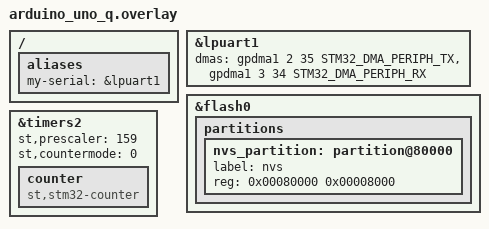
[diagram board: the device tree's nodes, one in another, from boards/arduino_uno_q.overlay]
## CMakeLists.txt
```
cmake_minimum_required(VERSION 3.20.0)

find_package(Zephyr REQUIRED HINTS $ENV{ZEPHYR_BASE})
project(imu_unoq_evk)

if(NOT DEFINED IMU_TARGET)
    set(IMU_TARGET "IM3J" CACHE STRING "IMU_TARGET is not defined, defaulting to IM3J")
endif()

if(IMU_TARGET STREQUAL "IM3J" OR IMU_TARGET STREQUAL "IM3J_STUB")
    set(IMU_INCLUDE_DIR ${CMAKE_CURRENT_SOURCE_DIR}/lib/IM3J)
    set(IMU_PLATFORM "IM3J")
elseif(IMU_TARGET STREQUAL "IM8S" OR IMU_TARGET STREQUAL "IM8S_STUB")
    set(IMU_INCLUDE_DIR ${CMAKE_CURRENT_SOURCE_DIR}/lib/IM8S)
    set(IMU_PLATFORM "IM8S")
else()
    message(FATAL_ERROR "Unsupported IMU_TARGET value: ${IMU_TARGET}")
endif()

if(IMU_TARGET STREQUAL "IM3J")
    target_compile_definitions(app PRIVATE -DSELECTED_PLATFORM_IM3J -DIMU_TARGET_IM3J)
    message(STATUS "Using IM3J code")
elseif(IMU_TARGET STREQUAL "IM3J_STUB")
    target_compile_definitions(app PRIVATE -DSELECTED_PLATFORM_IM3J -DIMU_TARGET_IM3J)
    message(STATUS "Using IM3J code (stub)")
elseif(IMU_TARGET STREQUAL "IM8S")
    target_compile_definitions(app PRIVATE -DSELECTED_PLATFORM_IM8S -DIMU_TARGET_IM8S)
    message(STATUS "Using IM8S code")
elseif(IMU_TARGET STREQUAL "IM8S_STUB")
    target_compile_definitions(app PRIVATE -DSELECTED_PLATFORM_IM8S -DIMU_TARGET_IM8S)
    message(STATUS "Using IM8S code (stub)")
endif()

if(IMU_TARGET STREQUAL "IM3J")
    add_library(DsImuSdk STATIC IMPORTED)
    set_target_properties(DsImuSdk PROPERTIES
        IMPORTED_LOCATION ${CMAKE_CURRENT_SOURCE_DIR}/lib/IM3J/DsImuSdk_Zephyr_CM33.a
    )
elseif(IMU_TARGET STREQUAL "IM8S")
    add_library(DsImuSdk STATIC IMPORTED)
    set_target_properties(DsImuSdk PROPERTIES
        IMPORTED_LOCATION ${CMAKE_CURRENT_SOURCE_DIR}/lib/IM8S/DsImuSdk_Zephyr_CM33.a
    )
elseif(IMU_TARGET STREQUAL "IM3J_STUB")
    add_library(DsImuSdk STATIC IMPORTED)
    set_target_properties(DsImuSdk PROPERTIES
        IMPORTED_LOCATION ${CMAKE_CURRENT_SOURCE_DIR}/lib/IM3J/DsImuSdk_placeholder.a
    )
elseif(IMU_TARGET STREQUAL "IM8S_STUB")
    add_library(DsImuSdk STATIC IMPORTED)
    set_target_properties(DsImuSdk PROPERTIES
        IMPORTED_LOCATION ${CMAKE_CURRENT_SOURCE_DIR}/lib/IM8S/DsImuSdk_placeholder.a
    )
endif()

target_include_directories(app PRIVATE
    ${CMAKE_CURRENT_SOURCE_DIR}/lib
    ${CMAKE_CURRENT_SOURCE_DIR}/src
    ${IMU_INCLUDE_DIR}
)

include_directories(${IMU_INCLUDE_DIR})

target_sources(app PRIVATE
    src/main.c
    src/zephyr_spi_hal.c
    src/zephyr_systick.c
    src/zephyr_async_uart.c
    src/uart_protocol.c
    src/Serial_Cmd.c
    src/nvs_config.c
)

target_compile_options(app PRIVATE
    -Wno-psabi
    -O2
)

target_link_libraries(app PRIVATE DsImuSdk stdc++)

set_property(TARGET app PROPERTY CXX_STANDARD 17)
```

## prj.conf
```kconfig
CONFIG_SPI=y
CONFIG_SPI_STM32=y
CONFIG_GPIO=y
CONFIG_PRINTK=y
CONFIG_LOG=y
CONFIG_LOG_DEFAULT_LEVEL=3

CONFIG_CPP=y
CONFIG_STD_CPP17=y
CONFIG_MINIMAL_LIBC=n
CONFIG_GLIBCXX_LIBCPP=y

CONFIG_HEAP_MEM_POOL_SIZE=65536
CONFIG_MAIN_STACK_SIZE=16384

CONFIG_CBPRINTF_FP_SUPPORT=y

CONFIG_FPU=y

CONFIG_SERIAL=y
CONFIG_UART_ASYNC_API=y
CONFIG_UART_INTERRUPT_DRIVEN=y

CONFIG_UART_CONSOLE=y

CONFIG_REBOOT=y

CONFIG_COUNTER=y
CONFIG_COUNTER_TIMER_STM32=y
CONFIG_CLOCK_CONTROL=y
CONFIG_SPEED_OPTIMIZATIONS=y

CONFIG_FLASH=y
CONFIG_FLASH_PAGE_LAYOUT=y
CONFIG_FLASH_MAP=y
CONFIG_MPU_ALLOW_FLASH_WRITE=y

CONFIG_SETTINGS=y
CONFIG_SETTINGS_NVS=y
CONFIG_NVS=y
CONFIG_MPU_ALLOW_FLASH_WRITE=y
```

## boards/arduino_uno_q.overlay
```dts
/ {
    aliases {
        my-serial = &lpuart1;
    };
};

&lpuart1 {
	dmas = <&gpdma1 2 35 STM32_DMA_PERIPH_TX>,
	       <&gpdma1 3 34 STM32_DMA_PERIPH_RX>;
	dma-names = "tx", "rx";
};

&flash0 {
    partitions {
        nvs_partition: partition@80000 {
            label = "nvs";
            reg = <0x00080000 0x00008000>;   /* 32 KB */
        };
    };
};

&timers2 {
    status = "okay";
    st,prescaler = <159>;  /* Set prescaler */
    st,countermode = <0>;         /* 0 = up-counting (default) */
    counter {
        compatible = "st,stm32-counter";
        status = "okay";
    };
};
```

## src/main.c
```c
#include <zephyr/kernel.h>
#include <zephyr/device.h>
#include <zephyr/drivers/spi.h>
#include <zephyr/drivers/counter.h>
#include <zephyr/drivers/gpio.h>
#include <zephyr/sys/printk.h>
#include <string.h>
#include <stdbool.h>

#include "DsImuSdk.h"
#include "zephyr_spi_hal.h"
#include "zephyr_async_uart.h"
#include "zephyr_systick.h"
#include "uart_protocol.h"
#include "nvs_config.h"

#define DsImuGetData_STACK_SIZE 3072
#define DsImuGetData_PRIORITY 6
#define UART1Send_STACK_SIZE 3072
#define UART1Send_PRIORITY 5
#define IMU_SAMPLE_PERIOD_US   (2000U)
#define IMU_FIFO_DATA_ARRAY_SIZE (10U)

K_THREAD_STACK_DEFINE(DsImuGetData_stack_area, DsImuGetData_STACK_SIZE);
K_THREAD_STACK_DEFINE(UART1Send_stack_area, UART1Send_STACK_SIZE);
K_SEM_DEFINE(uart_output, 0, 10);
K_SEM_DEFINE(imu_sample, 0, 10);

static const struct device* g_pCounter_dev = DEVICE_DT_GET(DT_CHILD(DT_NODELABEL(timers2), counter));

#define TIMER_NODE DT_ALIAS(my_counter)
static struct counter_alarm_cfg g_xImuSampleAlarm_cfg;
static struct counter_alarm_cfg g_xUartOutputAlarm_cfg;

static uint8_t SerialSendBuffer[SERIAL_SEND_BUFFER_SIZE];
static uint8_t UcSerialCmdBuffer[SERIAL_CMD_BUFF_SIZE];

bool gImuOutputEnabled = false;
bool gImuReinitFlag = false;
bool gImuSerialOutputEnabled = true;

static uint16_t SerialBufferIdx = 0;
static uint32_t sRxLen = 0;
//static uint32_t sUartProcDelayCompUs = 100;

static uint32_t gUartCurrentBaud = 921600U;   // Actual hardware baud rate
static uint32_t gUartDataBaud = 921600U;      // Configured baud rate for data output

static uint32_t gUartSendPeriodUs = 10000U;
/* Compensation control variables */
static uint64_t g_u64UartOutputExpectedUs = 0U;
static uint64_t g_u64ImuSampleExpectedUs = 0U;

typedef struct {
    DsImu_ImuCorrectedDataType xImuCorDataArray[IMU_FIFO_DATA_ARRAY_SIZE];
    uint8_t u8LatestIndex;
} Imu_Fifo_t;

static Imu_Fifo_t g_xImuFifo;

struct k_thread DsImuGetData_thread;
struct k_thread UART1Send_thread;

__attribute__((constructor(101))) static void __early_disable_alignment_check(void)
{
    *(volatile uint32_t*)0xE000ED14 &= ~(1UL << 3);
    __asm__ volatile("dsb sy" : : : "memory");
    __asm__ volatile("isb sy" : : : "memory");
}

void EnsureAlignmentCheckDisabled(void)
{
    static uint8_t checked = 0;
    if (!checked)
    {
        *(volatile uint32_t*)0xE000ED14 &= ~(1UL << 3);
        __asm__ volatile("dsb sy");
        __asm__ volatile("isb sy");
        checked = 1;
    }
}

static void Imu_fifo_push(const DsImu_ImuCorrectedDataType xImuCorData)
{
    uint8_t u8LatestIndex = g_xImuFifo.u8LatestIndex;
    u8LatestIndex = (u8LatestIndex + 1U) % IMU_FIFO_DATA_ARRAY_SIZE;
    (void)memcpy(&g_xImuFifo.xImuCorDataArray[u8LatestIndex], &xImuCorData, sizeof(DsImu_ImuCorrectedDataType));
    g_xImuFifo.u8LatestIndex = u8LatestIndex;
    if (g_xImuFifo.u8LatestIndex > IMU_FIFO_DATA_ARRAY_SIZE - 1U) {
        g_xImuFifo.u8LatestIndex = IMU_FIFO_DATA_ARRAY_SIZE - 1U;
    }
}

static void timer_callback(const struct device* dev, uint8_t chan_id, uint32_t ticks, void* user_data)
{
    (void)ticks;
    (void)user_data;
    uint64_t u64NowUs = k_cyc_to_us_floor64(k_cycle_get_64());
    int64_t i64Drift = 0;
    uint64_t u64AlarmUs = 0U;
    if (0U == chan_id) {
        /* Calculate expected trigger time */
        if (0U == g_u64ImuSampleExpectedUs) {
            /* First trigger, initialize */
            g_u64ImuSampleExpectedUs = u64NowUs;
        }
        else {
            g_u64ImuSampleExpectedUs += IMU_SAMPLE_PERIOD_US;
        }
        /* Calculate drift (positive = late, negative = early) */
        i64Drift = (int64_t)(u64NowUs - g_u64ImuSampleExpectedUs);

        /* ========== Core compensation algorithm ========== */
        /* If drift positive (late), advance next; if negative (early), delay next */
        u64AlarmUs = (uint64_t)((int64_t)IMU_SAMPLE_PERIOD_US - i64Drift);
        if ((u64AlarmUs < (IMU_SAMPLE_PERIOD_US - 100U)) || (u64AlarmUs > (IMU_SAMPLE_PERIOD_US + 100U))) {
            u64AlarmUs = IMU_SAMPLE_PERIOD_US;
        }
        g_xImuSampleAlarm_cfg.ticks = counter_us_to_ticks(dev, u64AlarmUs);
        //printk("now_us:%llu,expected_us:%llu,drift:%lld,alarm_us:%llu us\n", u64NowUs, g_u64ImuSampleExpectedUs, i64Drift, u64AlarmUs);
        if (true == gImuOutputEnabled) {
            counter_set_channel_alarm(dev, chan_id, &g_xImuSampleAlarm_cfg);
        }

        k_sem_give(&imu_sample);
    }
    else if (1U == chan_id) {
        /* Calculate expected trigger time */
        if (0U == g_u64UartOutputExpectedUs) {
            /* First trigger, initialize */
            g_u64UartOutputExpectedUs = u64NowUs;
        }
        else {
            g_u64UartOutputExpectedUs += gUartSendPeriodUs;
        }
        /* Calculate drift (positive = late, negative = early) */
        i64Drift = (int64_t)(u64NowUs - g_u64UartOutputExpectedUs);

        /* ========== Core compensation algorithm ========== */
        /* If drift positive (late), advance next; if negative (early), delay next */
        u64AlarmUs = (uint64_t)((int64_t)gUartSendPeriodUs - i64Drift);
        if ((u64AlarmUs < (gUartSendPeriodUs - 100U)) || (u64AlarmUs > (gUartSendPeriodUs + 100U))) {
            u64AlarmUs = gUartSendPeriodUs;
        }

        g_xUartOutputAlarm_cfg.ticks = counter_us_to_ticks(dev, u64AlarmUs);
        //printk("now_us:%llu,expected_us:%llu,drift:%lld,alarm_us:%llu us\n", u64NowUs, g_u64UartOutputExpectedUs, i64Drift, u64AlarmUs);

        counter_set_channel_alarm(dev, chan_id, &g_xUartOutputAlarm_cfg);
        k_sem_give(&uart_output);
    }
    else { /* do nothing. */
    }
}

static void UartCmdRxCallback(uint8_t* data, size_t len);

#if defined(IMU_TARGET_IM3J)
DsImu_CfgInfoType CfgInfo = {
    .module_type = MODULE_IM3J,
    .acc_fs = IM3J_FS_XL_6_G, /**< Accelerometer full-scale code. */
    .gyr_fs = IM3J_FS_GY_1000_DPS, /**< Gyroscope full-scale code. */
    .acc_odr = IM3J_XL_ODR_200_HZ, /**< Accelerometer output data rate. */
    .acc_lpf = IM3J_XL_LPF_OSR4, /**< Accelerometer low-pass filter. */
    .gyr_lpf = IM3J_GY_ODR_200_LPF_23_HZ, /**< Gyroscope ODR and LPF. */
    .tim_freq = FREQ_500HZ, /**< Timer frequency [Hz]. */
    .u32SpiTimeoutUs[0] = 10000U, /**< [us] */
    .u32SpiTimeoutUs[1] = 10000U, /**< [us] */
    .u64UsTickValueMax = 0xFFFFFFFFFFFFFFFFU,
    .mcu_freq = 160U,
    .transfer = spiTransfer,
    .cancel = spiCancel,
    .systick = GetTickUs,
    .getStatus = spiGetTransferResult,
    .fMntAng = {0.0F, 0.0F, 0.0F},
    .fExtAng = {0.0F, 0.0F, 0.0F},
    .fPos = {0.0F, 0.0F, 0.0F}
};

#elif defined(IMU_TARGET_IM8S)
DsImu_CfgInfoType CfgInfo = {
    .module_type = MODULE_IM8S,
    .acc_fs = IM8S_FS_XL_8_G, /**< Accelerometer full-scale code. */
    .gyr_fs = IM8S_FS_GY_250_DPS, /**< Gyroscope full-scale code. */
    .acc_odr = BYPASS, /**< Accelerometer ODR. */
    .acc_lpf = IM8S_XL_LPF_16HZ, /**< Accelerometer low-pass filter. */
    .gyr_lpf = IM8S_GY_LPF_50HZ, /**< Gyroscope low-pass filter. */
    .tim_freq = FREQ_500HZ, /**< Timer frequency [Hz]. */
    .u32SpiTimeoutUs[0] = 10000U, /**< [us] */
    .u32SpiTimeoutUs[1] = 10000U, /**< [us] */
    .u64UsTickValueMax = 0xFFFFFFFFFFFFFFFFU,
    .mcu_freq = 160U,
    .transfer = spiTransfer,
    .cancel = spiCancel,
    .systick = GetTickUs,
    .getStatus = spiGetTransferResult,
    .fMntAng = {0.0F, 0.0F, 0.0F},
    .fExtAng = {0.0F, 0.0F, 0.0F},
    .fPos = {0.0F, 0.0F, 0.0F}
};
#endif

static DsImu_ImuCorrectedDataType xImuCorData;
static DsImu_ImuRawDataType xImuRawData;
static DsImu_InfoType xInfo;
static bool sDsImuSdkInitFlag = false;

static void Counter_Config(const struct device* counter_dev)
{
    int ret = 0;
    uint32_t u32ImuSamplePeriodUs = IMU_SAMPLE_PERIOD_US;  /* 2ms */
    uint32_t u32ImuSampleAlarmTicks = 0U;
    uint32_t u32UartOutputPeriodUs = gUartSendPeriodUs;
    uint32_t u32UartOutputAlarmTicks = 0U;

    if (!device_is_ready(counter_dev)) {
        printk("Counter device not ready!\n");
        return;
    }
    printk("Counter device found: %s\n", counter_dev->name);

    /* Get timer actual frequency (for validation) */
    uint32_t freq = counter_get_frequency(counter_dev);
    printk("Timer frequency: %u Hz\n", freq);

    /* Convert Imu microseconds to ticks (based on actual frequency) */
    u32ImuSampleAlarmTicks = counter_us_to_ticks(counter_dev, u32ImuSamplePeriodUs);
    printk("ImuSamplePeriodUs: %u us -> %u ticks\n", u32ImuSamplePeriodUs, u32ImuSampleAlarmTicks);
    g_xImuSampleAlarm_cfg.callback = timer_callback;
    g_xImuSampleAlarm_cfg.ticks = u32ImuSampleAlarmTicks;
    g_xImuSampleAlarm_cfg.user_data = NULL;
    g_xImuSampleAlarm_cfg.flags = 0U;

    //   ret = counter_set_channel_alarm(counter_dev, 0, &g_xImuSampleAlarm_cfg);
    //   if (ret != 0) {
    //       printk("Failed to set alarm (err: %d)\n", ret);
    //       return;
    //   }

    u32UartOutputAlarmTicks = counter_us_to_ticks(counter_dev, u32UartOutputPeriodUs);
    printk("UartOutputPeriodUs: %u us -> %u ticks\n", u32UartOutputPeriodUs, u32UartOutputAlarmTicks);
    g_xUartOutputAlarm_cfg.callback = timer_callback;
    g_xUartOutputAlarm_cfg.ticks = u32UartOutputAlarmTicks;
    g_xUartOutputAlarm_cfg.user_data = NULL;
    g_xUartOutputAlarm_cfg.flags = 0U;

    ret = counter_set_channel_alarm(counter_dev, 1, &g_xUartOutputAlarm_cfg);
    if (ret != 0) {
        printk("Failed to set alarm (err: %d)\n", ret);
        return;
    }

    ret = counter_start(counter_dev);
    if (ret != 0) {
        printk("Failed to start counter (err: %d)\n", ret);
        return;
    }

    printk("Timer started!\n");
}

// static uint64_t g_u64LastTick = 0U;
void DsImuGetData_entry_point(void* p1, void* p2, void* p3)
{
#if defined(IMU_TARGET_IM3J)
    for (;;)
    {
        if ((gImuOutputEnabled == false) || (gImuReinitFlag))
        {
            if (gImuReinitFlag)
            {
                gImuReinitFlag = 0;
                //printk("Reinit IMU...\n");
            }
            else
            {
                //printk("IMU First Start...\n");
            }

            if (DsImu_Init(&CfgInfo) == 0)
            {
                //printk("DsImu SDK Init Success!\n");
                gImuOutputEnabled = true;
                g_u64ImuSampleExpectedUs = 0U;
                counter_set_channel_alarm(g_pCounter_dev, 0, &g_xImuSampleAlarm_cfg);
            }
            else
            {
                //printk("IMU Init FAIL\n");
            }
        }
        k_sem_take(&imu_sample, K_FOREVER);
        //uint64_t u64Us = k_cyc_to_us_floor64(k_cycle_get_64());
        //uint64_t u64diff = u64Us - g_u64LastTick;
        //g_u64LastTick = u64Us;
        //uint64_t u64Us2 = 0U;
        //uint64_t u64Us3 = 0U;
        if (gImuOutputEnabled)
        {
            //u64Us2 = k_cyc_to_us_floor64(k_cycle_get_64());
            DsImuGetDataStatus_t eGetDataStatus =
                DsImu_GetData(&xImuCorData, &xImuRawData);
            //u64Us3 = k_cyc_to_us_floor64(k_cycle_get_64());
            Imu_fifo_push(xImuCorData);
            if (eGetDataStatus == GET_SUCCESS)
            {

            }
            else if (eGetDataStatus == GET_DATA_NOT_READY)
            {

            }
            else if (eGetDataStatus == GET_ERR_RESET)
            {
                gImuOutputEnabled = false;
                gImuReinitFlag = true;
            }
            else
            {
                //printk("DsImu Get Data Error! Code: %d\n", eGetDataStatus);
            }
        }
        //printk("Tick:%llu, diff:%llu us, GetDataRun:%llu us\n", u64Us, u64diff, u64Us3 - u64Us2);
//k_msleep(10);
    }

#elif defined(IMU_TARGET_IM8S)

    for (;;)
    {
        if ((gImuOutputEnabled == false) || (gImuReinitFlag))
        {
            if (gImuReinitFlag)
            {
                gImuReinitFlag = 0;
                //printk("Reinit IMU...\n");
            }
            else
            {
                //printk("IMU First Start...\n");
            }

            DsImuInitStatus_t ret = DsImu_Init(&CfgInfo);

            if (ret == INIT_SUCCESS)
            {
                gImuOutputEnabled = true;
                //printk("DsImu SDK Init Success!\n");
                uint8_t eStatus_GetInfo = DsImu_GetInfo(&xInfo);
                if (eStatus_GetInfo == 0U)
                {
                    //printk("DsImu SDK GetInfo Success!\n");
                }
                else {
                    //printk("DsImu SDK GetInfo Failed! Error Code: %d\n", eStatus_GetInfo);
                }
                sDsImuSdkInitFlag = true;
                g_u64ImuSampleExpectedUs = 0U;
                counter_set_channel_alarm(g_pCounter_dev, 0, &g_xImuSampleAlarm_cfg);
            }
            else
            {
                //printk("IMU Init FAIL! Error Code:%d\n", ret);
            }
        }
        k_sem_take(&imu_sample, K_FOREVER);
        //uint64_t u64Us = k_cyc_to_us_floor64(k_cycle_get_64());
        //uint64_t u64diff = u64Us - g_u64LastTick;
        //g_u64LastTick = u64Us;
        //uint64_t u64Us2 = 0U;
        //uint64_t u64Us3 = 0U;
        if (gImuOutputEnabled)
        {
            //u64Us2 = k_cyc_to_us_floor64(k_cycle_get_64());
            DsImuGetDataStatus_t eGetDataStatus =
                DsImu_GetData(&xImuCorData, &xImuRawData);
            //u64Us3 = k_cyc_to_us_floor64(k_cycle_get_64());
            Imu_fifo_push(xImuCorData);
            if (eGetDataStatus == GET_SUCCESS)
            {

            }
            else if (eGetDataStatus == GET_ERR_RESET)
            {
                gImuOutputEnabled = false;
                gImuReinitFlag = true;
            }
            else
            {
                //printk("DsImu Get Data Error! Code: %d\n", eGetDataStatus);
            }
        }
        //printk("Tick:%llu, diff:%llu us, GetDataRun:%llu us\n", u64Us, u64diff, u64Us3 - u64Us2);
//k_msleep(10);
    }
#endif
}

void UART1Send_entry_point(void* p1, void* p2, void* p3)
{
    while (1)
    {
        /* Wait for semaphore (block until data available) */
        k_sem_take(&uart_output, K_FOREVER);
        //uint64_t u64Us = k_cyc_to_us_floor64(k_cycle_get_64());
        //uint64_t u64diff = u64Us - g_u64LastTick;
        //g_u64LastTick = u64Us;
        if (gImuSerialOutputEnabled)
        {
            SerialBufferIdx = Composer_PrintImu(
                SerialSendBuffer,
                &g_xImuFifo.xImuCorDataArray[g_xImuFifo.u8LatestIndex]);

            SerialSendMsg(
                SerialSendBuffer,
                SerialBufferIdx);
            //printk("Tick:%llu, diff: %llu us\n", u64Us, u64diff);
            //printk("Running!\r\n");
        }
        //k_usleep(gUartSendPeriodUs - sUartProcDelayCompUs);
    }
}

void setUartSendPeriodUs(const uint32_t u32UartSendPeriodUs)
{
    gUartSendPeriodUs = u32UartSendPeriodUs;
    g_u64UartOutputExpectedUs = 0U;
    //printk("UartSetPeriod:%u\n", gUartSendPeriodUs);
}

uint32_t GetUartSendPeriodUs(void) { return gUartSendPeriodUs; }

// Current hardware baud rate
void setUartCurrentBaud(const uint32_t baud) { gUartCurrentBaud = baud; }
uint32_t GetUartCurrentBaud(void) { return gUartCurrentBaud; }

// Configured baud rate for data output
void setUartBaud(const uint32_t baud) { gUartDataBaud = baud; }
uint32_t GetUartBaud(void) { return gUartDataBaud; }


int main(void)
{
    EnsureAlignmentCheckDisabled();
    UartRxCbRegister(UartCmdRxCallback);

    const struct device* spi_dev = DEVICE_DT_GET(DT_NODELABEL(spi2));
    if (!device_is_ready(spi_dev))
    {
        //printk("SPI2 not ready\n");
        return 0;
    }

    //counter_dev = DEVICE_DT_GET_ANY(st_stm32_counter);
    if (g_pCounter_dev) {
        printk("The selected counter device is: %s\n", g_pCounter_dev->name);
    }

    TickInit();
    Zephyr_SPI_GPIO_Init();

    /* ====== Load NVS configuration ====== */
    int nvs_rc = NvsConfigInit();
    if (nvs_rc == 0) {
        StoredConfig_t stored;
        if (NvsConfigLoad(&stored) == 0) {
            /* Override default values */
            gUartDataBaud = stored.baud_rate;
            gUartSendPeriodUs = stored.send_period_us;
            CfgInfo.acc_fs = stored.acc_fs;
            CfgInfo.gyr_fs = stored.gyr_fs;
            CfgInfo.acc_odr = stored.acc_odr;
            CfgInfo.acc_lpf = stored.acc_lpf;
            CfgInfo.gyr_lpf = stored.gyr_lpf;
            printk("NVS: config loaded, baud=%u, period=%u\n",
                gUartDataBaud, gUartSendPeriodUs);
        }
    }

    Counter_Config(g_pCounter_dev);

    (void)memset(&g_xImuFifo.xImuCorDataArray[0], 0, sizeof(DsImu_ImuCorrectedDataType));
    g_xImuFifo.u8LatestIndex = 9U;

    k_thread_create(&DsImuGetData_thread,
        DsImuGetData_stack_area,
        K_THREAD_STACK_SIZEOF(DsImuGetData_stack_area),
        DsImuGetData_entry_point,
        NULL, NULL, NULL,
        DsImuGetData_PRIORITY,
        0,
        K_NO_WAIT);

    k_thread_create(&UART1Send_thread,
        UART1Send_stack_area,
        K_THREAD_STACK_SIZEOF(UART1Send_stack_area),
        UART1Send_entry_point,
        NULL, NULL, NULL,
        UART1Send_PRIORITY,
        0,
        K_NO_WAIT);
    return 0;
}

static void UartCmdRxCallback(uint8_t* data, size_t len)
{
    for (int i = 0; i < len; i++)
    {
        uint8_t byte = data[i];

        if (sRxLen >= SERIAL_CMD_BUFF_SIZE)
        {
            sRxLen = 0;
        }

        UcSerialCmdBuffer[sRxLen++] = byte;

        if (byte == '\n')
        {
            ProcessSerialBuffer(UcSerialCmdBuffer, &sRxLen);
        }
    }

    k_free(data);
}
```

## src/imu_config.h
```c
#ifndef IMU_CONFIG_H
#define IMU_CONFIG_H

#include "DsImuSdk.h"

extern DsImu_CfgInfoType CfgInfo;

#endif
```

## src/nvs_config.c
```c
#include "nvs_config.h"
#include <zephyr/kernel.h>
#include <zephyr/device.h>
#include <zephyr/drivers/flash.h>
#include <zephyr/storage/flash_map.h>
#include <zephyr/kvss/nvs.h>
#include <string.h>

/* ====== Obtain partition information directly using devicetree ====== */
#define NVS_PARTITION_NODE  DT_NODELABEL(nvs_partition)

#define NVS_FLASH_DEVICE    DEVICE_DT_GET(DT_MTD_FROM_FIXED_PARTITION(NVS_PARTITION_NODE))
#define NVS_OFFSET          DT_REG_ADDR(NVS_PARTITION_NODE)
#define NVS_SIZE            DT_REG_SIZE(NVS_PARTITION_NODE)

#define NVS_SECTOR_SIZE     8192U
#define NVS_SECTOR_COUNT    (NVS_SIZE / NVS_SECTOR_SIZE)

static struct nvs_fs g_nvs_fs;
static bool g_nvs_ready = false;

static uint8_t Config_CRC8(const uint8_t* buf, uint16_t len)
{
    uint8_t crc = 0;
    for (uint16_t i = 0; i < len; i++) {
        crc ^= buf[i];
        for (uint8_t j = 0; j < 8; j++) {
            if (crc & 0x80)
                crc = (crc << 1) ^ 0x07;
            else
                crc <<= 1;
        }
    }
    return crc;
}

/* ====== Initialize NVS ====== */
int NvsConfigInit(void)
{
    int rc;

    if (!device_is_ready(NVS_FLASH_DEVICE)) {
        printk("NVS: Flash device not ready\n");
        return -ENODEV;
    }

    g_nvs_fs.flash_device = NVS_FLASH_DEVICE;
    g_nvs_fs.offset = NVS_OFFSET;
    g_nvs_fs.sector_size = NVS_SECTOR_SIZE;
    g_nvs_fs.sector_count = NVS_SECTOR_COUNT;

    rc = nvs_mount(&g_nvs_fs);
    if (rc) {
        printk("NVS: mount failed (%d), formatting...\n", rc);
        /* Perform a clean installation or data restoration if it is the first time use or if the data is damaged. */
        rc = nvs_clear(&g_nvs_fs);
        if (rc) {
            printk("NVS: clear failed: %d\n", rc);
            return rc;
        }
        rc = nvs_mount(&g_nvs_fs);
        if (rc) {
            printk("NVS: re-mount after clear failed: %d\n", rc);
            return rc;
        }
    }

    g_nvs_ready = true;
    printk("NVS: ready, offset=0x%lx, size=%u\n",
        (unsigned long)NVS_OFFSET, (unsigned int)NVS_SIZE);
    return 0;
}

/* ====== Load configuration ====== */
int NvsConfigLoad(StoredConfig_t* cfg)
{
    ssize_t read_len;

    if (!cfg)      return -EINVAL;
    if (!g_nvs_ready) return -EAGAIN;

    read_len = nvs_read(&g_nvs_fs, NVS_ID_CONFIG, cfg, sizeof(StoredConfig_t));
    if (read_len < 0) {
        printk("NVS: config not found (rc=%d), using defaults\n", (int)read_len);
        return 1;  /* No stored data uses default values */
    }
    if (read_len != sizeof(StoredConfig_t)) {
        printk("NVS: config size mismatch (%d != %d)\n",
            (int)read_len, (int)sizeof(StoredConfig_t));
        return -EIO;
    }

    /* Verify magic */
    if (cfg->magic != NVS_CONFIG_MAGIC) {
        printk("NVS: bad magic 0x%08X (expected 0x%08X)\n",
            (unsigned)cfg->magic, (unsigned)NVS_CONFIG_MAGIC);
        return 1;
    }

    uint8_t calc_crc = Config_CRC8((const uint8_t*)cfg,
        sizeof(StoredConfig_t) - 3);
    if (calc_crc != cfg->crc) {
        printk("NVS: CRC mismatch (calc=0x%02X, stored=0x%02X)\n",
            calc_crc, cfg->crc);
        return -EIO;
    }

    printk("NVS: config loaded OK\n");
    return 0;
}

/* ====== Save configuration ====== */
int NvsConfigSave(const StoredConfig_t* cfg)
{
    int rc;
    StoredConfig_t wr_cfg;

    if (!cfg)         return -EINVAL;
    if (!g_nvs_ready) return -EAGAIN;

    memcpy(&wr_cfg, cfg, sizeof(StoredConfig_t));
    wr_cfg.magic = NVS_CONFIG_MAGIC;
    wr_cfg.crc = Config_CRC8((const uint8_t*)&wr_cfg,
        sizeof(StoredConfig_t) - 3);
    wr_cfg.reserved[0] = 0xFF;
    wr_cfg.reserved[1] = 0xFF;

    rc = nvs_write(&g_nvs_fs, NVS_ID_CONFIG, &wr_cfg, sizeof(StoredConfig_t));
    if (rc < 0) {
        printk("NVS: write failed: %d\n", rc);
        return rc;
    }

    printk("NVS: config saved OK\n");
    return 0;
}

/* ====== Erasure of configuration ====== */
int NvsConfigErase(void)
{
    if (!g_nvs_ready) return -EAGAIN;

    int rc = nvs_delete(&g_nvs_fs, NVS_ID_CONFIG);
    if (rc < 0 && rc != -ENOENT) {
        printk("NVS: erase failed: %d\n", rc);
        return rc;
    }
    printk("NVS: config erased\n");
    return 0;
}
```

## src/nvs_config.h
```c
#ifndef NVS_CONFIG_H
#define NVS_CONFIG_H

#include <stdint.h>
#include <stdbool.h>

#define NVS_CONFIG_MAGIC    0xDA15C401   /* "UIMU" */

#if defined(IMU_TARGET_IM3J)
#define NVS_ID_CONFIG       0x0001       /* Configuration of IM3J*/
#elif defined(IMU_TARGET_IM8S)
#define NVS_ID_CONFIG       0x0002       /* Configuration of IM8S*/
#else
#define NVS_ID_CONFIG       0x0001       /* default */
#endif

typedef struct __attribute__((packed)) {
    uint32_t magic;           /* Magic number, used to determine whether it has been written before */
    uint32_t baud_rate;       /* gUartDataBaud */
    uint32_t send_period_us;  /* gUartSendPeriodUs */
    uint8_t  acc_fs;          /* CfgInfo.acc_fs */
    uint8_t  gyr_fs;          /* CfgInfo.gyr_fs */
    uint8_t  acc_odr;         /* CfgInfo.acc_odr */
    uint8_t  acc_lpf;         /* CfgInfo.acc_lpf */
    uint8_t  gyr_lpf;         /* CfgInfo.gyr_lpf */
    uint8_t  crc;             /* CRC */
    uint8_t  reserved[2];     /* Align and pad */
} StoredConfig_t;

/**
 * @brief Initialize NVS (mount partition)
 * @return 0 on success, negative on failure
 */
int NvsConfigInit(void);

/**
 * @brief Load configuration from NVS
 * @param cfg Output parameter, loaded into this structure
 * @return 0=success, 1=no stored data (first boot), negative=error
 */
int NvsConfigLoad(StoredConfig_t* cfg);

/**
 * @brief Save configuration to NVS
 * @param cfg Configuration to be saved
 * @return 0 on success, negative on failure
 */
int NvsConfigSave(const StoredConfig_t* cfg);

/**
 * @brief Erase configuration in NVS (for factory reset)
 * @return 0 on success, negative on failure
 */
int NvsConfigErase(void);

#endif /* NVS_CONFIG_H */
```

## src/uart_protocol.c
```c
#include "uart_protocol.h"
#include <stdio.h>
#include <string.h>
#include "zephyr_systick.h"
#include "DsImuSdk.h"

uint8_t u8count;
uint8_t u8bincount;
uint8_t crc_ack;
int16_t i16temp;

uint8_t CRC_8(uint8_t* buf, uint16_t len)
{
    uint8_t crc = 0;

    for (uint16_t i = 0; i < len; i++)
    {
        crc ^= buf[i];
        for (uint8_t j = 0; j < 8; j++)
        {
            if (crc & 0x80)
                crc = (crc << 1) ^ 0x07;
            else
                crc <<= 1;
        }
    }
    return crc;
}

int Composer_PrintImu(unsigned char* pStr, DsImu_ImuCorrectedDataType* pxSendData)
{
    uint8_t u8binhead[3] = { 0XA5, 0X5A, 0X00 };
    uint8_t u8end[2] = { 0X0D, 0X0A };
    uint64_t u64UnixTime;
    uint8_t u8cmdlen[2] = { 0X10, 0X40 };
    uint8_t idx = 0;
    int16_t i16temp;
    uint8_t crc_ack;

    if (u8bincount < 255) {
        u8bincount++;
    }
    else {
        u8bincount = 0;
    }

    memcpy(pStr, u8binhead, 3);
    idx += 3;

    memcpy(pStr + idx, u8cmdlen, 2);
    idx += 2;

    memcpy(pStr + idx, &u8bincount, 1);
    idx += 1;

    u64UnixTime = (uint64_t)k_uptime_get();
    // u64UnixTime = GetTickUs(); 
    memcpy(pStr + idx, &u64UnixTime, 8);
    idx += 8;

    memcpy(pStr + idx, pxSendData->fAlignedAcceleration, 12);
    idx += 12;

    memcpy(pStr + idx, pxSendData->fAlignedAngularRate, 12);
    idx += 12;

    memcpy(pStr + idx, &pxSendData->fAttitude[1], 4);
    idx += 4;
    memcpy(pStr + idx, &pxSendData->fAttitude[2], 4);
    idx += 4;
    memcpy(pStr + idx, &pxSendData->fAttitude[0], 4);
    idx += 4;

    memcpy(pStr + idx, pxSendData->fQuat, 16);
    idx += 16;

    i16temp = 10 * pxSendData->fTemperature;
    memcpy(pStr + idx, &i16temp, 2);
    idx += 2;

    *(pStr + idx) = pxSendData->u16AhrsStatus & 0xFFU;
    idx += 1;

    crc_ack = CRC_8(pStr, idx);
    memcpy(pStr + idx, &crc_ack, 1);
    idx += 1;

    memcpy(pStr + idx, u8end, 2);
    idx += 2;

    return idx;
}
```

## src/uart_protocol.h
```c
#ifndef UART_PROTOCOL_H_
#define UART_PROTOCOL_H_

#include <stdint.h>
#include <stdbool.h>
#include "DsImuSdk.h"

int Composer_PrintImu(unsigned char* pStr, DsImu_ImuCorrectedDataType* pxSendData);
uint8_t CRC_8(uint8_t* buf, uint16_t len);
void setUartSendPeriodUs(const uint32_t u32UartSendPeriodUs);
uint32_t GetUartSendPeriodUs(void);

void setUartBaud(const uint32_t u32UartBaud);
void setUartCurrentBaud(const uint32_t u32UartBaud);
uint32_t GetUartBaud(void);
uint32_t GetUartCurrentBaud(void);

#endif /* Serial_H_ */
```

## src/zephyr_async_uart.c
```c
#include <zephyr/kernel.h>
#include <zephyr/device.h>
#include <zephyr/devicetree.h>
#include <zephyr/drivers/uart.h>
#include <string.h>
#include <zephyr/logging/log.h>
#include "zephyr_async_uart.h"
#include "uart_protocol.h"

#define UART_ALIAS DT_ALIAS(my_serial)
#define RX_BUF_SIZE 128
#define RX_BUF_NUM 4
#define RX_TIMEOUT_US 2000

LOG_MODULE_REGISTER(app_uart, LOG_LEVEL_INF);

struct uart_packet
{
    uint8_t* data;
    size_t len;
};

static const struct device* UartDevice = DEVICE_DT_GET(UART_ALIAS);
static K_SEM_DEFINE(tx_done, 0, 1);
static packets_cb_t user_rx_cb = NULL;
uint8_t Serial_ucAckBuffer[256] = { 0 };

K_MEM_SLAB_DEFINE(uart_rx_slab, RX_BUF_SIZE, RX_BUF_NUM, 4);
K_MSGQ_DEFINE(rx_msgq, sizeof(struct uart_packet), 10, 4);
K_MSGQ_DEFINE(tx_msgq, sizeof(struct uart_packet), 10, 4);

static void uart_event_handler(const struct device* dev,
    struct uart_event* evt,
    void* user_data);
static int AppUartInit(void);
static void AppUartTxThread(void* arg1, void* arg2, void* arg3);
static void AppUartRxThread(void* arg1, void* arg2, void* arg3);

static void uart_event_handler(const struct device* dev,
    struct uart_event* evt,
    void* user_data)
{
    int err;

    switch (evt->type)
    {
        case UART_TX_DONE:
            k_sem_give(&tx_done);
            break;

        case UART_RX_RDY:
            // LOG_INF("RX event! len=%d", evt->data.rx.len);
            uint8_t* rx_data = evt->data.rx.buf + evt->data.rx.offset;
            size_t rx_len = evt->data.rx.len;

            uint8_t* heap_buf = k_malloc(rx_len);
            if (!heap_buf)
            {
                LOG_ERR("Heap alloc failed for RX");
                break;
            }

            memcpy(heap_buf, rx_data, rx_len);

            struct uart_packet pkt = { .data = heap_buf, .len = rx_len };
            k_msgq_put(&rx_msgq, &pkt, K_NO_WAIT);
            break;

        case UART_RX_BUF_REQUEST:
            uint8_t* new_buf;
            err = k_mem_slab_alloc(&uart_rx_slab, (void**)&new_buf, K_NO_WAIT);
            if (err)
            {
                LOG_ERR("Slab alloc failed!");
                break;
            }
            uart_rx_buf_rsp(UartDevice, new_buf, RX_BUF_SIZE);
            break;

        case UART_RX_BUF_RELEASED:
            k_mem_slab_free(&uart_rx_slab, (void*)evt->data.rx_buf.buf);
            break;

        default:
            break;
    }
}

static int AppUartInit(void)
{
    LOG_INF("AppUartInit running");
    // LOG_INF("UartDevice=%p, ready=%d, name=%s", UartDevice, device_is_ready(UartDevice), UartDevice ? UartDevice->name : "NULL");

    struct uart_config cfg;
    uart_config_get(UartDevice, &cfg);
    cfg.baudrate = 921600;
    uart_configure(UartDevice, &cfg);
    setUartCurrentBaud(921600);

    uint8_t* first_buf;
    int err;

    if (!device_is_ready(UartDevice))
    {
        LOG_ERR("UART device not ready");

        return -ENODEV;
    }

    uart_callback_set(UartDevice, uart_event_handler, NULL);

    err = k_mem_slab_alloc(&uart_rx_slab, (void**)&first_buf, K_NO_WAIT);
    if (err)
        return err;

    err = uart_rx_enable(UartDevice, first_buf, RX_BUF_SIZE, RX_TIMEOUT_US);
    if (err)
    {
        k_mem_slab_free(&uart_rx_slab, (void*)first_buf);
        return err;
    }

    return 0;
}

uint8_t Hex2Char(uint8_t c, bool* pbOk)
{
    uint8_t u8Result = 0U;

    if (pbOk != NULL) {
        *pbOk = true;
    }

    if ((c >= 0) && (c <= 9)) {
        u8Result = c + '0';
    }
    else if (c >= 0x0a && c <= 0x0f) {
        u8Result = c + 'A' - 0x0a;
    }
    return u8Result;
}

int UartRxCbRegister(packets_cb_t cb)
{
    if (!cb)
        return -EINVAL;
    user_rx_cb = cb;
    return 0;
}

int SerialSendMsg(const uint8_t* data, size_t len)
{
    if (!data || len == 0)
        return -EINVAL;

    uint8_t* tx_copy = k_malloc(len);
    if (!tx_copy)
        return -ENOMEM;

    memcpy(tx_copy, data, len);

    struct uart_packet pkt = { .data = tx_copy, .len = len };
    return k_msgq_put(&tx_msgq, &pkt, K_NO_WAIT);
}

void SendOnlyNAck(void)
{
    const char* msg = "$DSIMC,NACK*ED\r\n";
    SerialSendMsg((const uint8_t*)msg, strlen(msg));
}

void SendAck(void)
{
    const char* msg = "$DSIMC,ACK*50\r\n";
    SerialSendMsg((const uint8_t*)msg, strlen(msg));
}

void SendERRWriteAck(uint8_t u8Addr, uint8_t rel)
{
    uint8_t crc_ack;
    bool c2h_flag;
    uint8_t u8length;

    sprintf(&Serial_ucAckBuffer[0], "$DSIMC,NACK,%02X,%02X\r\n", u8Addr, rel);
    u8length = strlen(Serial_ucAckBuffer);

    Serial_ucAckBuffer[u8length - 2] = '*';
    crc_ack = CRC_8(Serial_ucAckBuffer, u8length - 2);
    Serial_ucAckBuffer[u8length - 1] = Hex2Char((crc_ack >> 4), &c2h_flag);
    Serial_ucAckBuffer[u8length] = Hex2Char((crc_ack & 0x0F), &c2h_flag);
    sprintf(&Serial_ucAckBuffer[u8length + 1], "\r\n");
    SerialSendMsg(Serial_ucAckBuffer, strlen(Serial_ucAckBuffer));
}

void SendReadWriteAck(uint8_t u8Addr, uint8_t u8Val)
{
    uint8_t crc_ack;
    bool c2h_flag;
    uint8_t u8length;

    sprintf(&Serial_ucAckBuffer[0], "$DSIMC,ACK,%02X,%02X\r\n", u8Addr, u8Val);
    u8length = strlen(Serial_ucAckBuffer);

    Serial_ucAckBuffer[u8length - 2] = '*';
    crc_ack = CRC_8(Serial_ucAckBuffer, u8length - 2);
    Serial_ucAckBuffer[u8length - 1] = Hex2Char((crc_ack >> 4), &c2h_flag);
    Serial_ucAckBuffer[u8length] = Hex2Char((crc_ack & 0x0F), &c2h_flag);
    sprintf(&Serial_ucAckBuffer[u8length + 1], "\r\n");
    SerialSendMsg(Serial_ucAckBuffer, strlen(Serial_ucAckBuffer));
}

int UartReconfig(uint32_t baudrate)
{
    // k_msleep(200);

    struct uart_config cfg;
    int err;

    uart_rx_disable(UartDevice);

    uart_config_get(UartDevice, &cfg);

    cfg.baudrate = baudrate;
    setUartCurrentBaud(baudrate);

    err = uart_configure(UartDevice, &cfg);
    if (err)
    {
        printk("UART reconfig failed: %d\n", err);
        return err;
    }

    uint8_t* buf;
    err = k_mem_slab_alloc(&uart_rx_slab, (void**)&buf, K_NO_WAIT);
    if (err)
    {
        printk("UART buf alloc failed\n");
        return err;
    }

    err = uart_rx_enable(UartDevice, buf, RX_BUF_SIZE, RX_TIMEOUT_US);
    if (err)
    {
        printk("UART rx enable failed\n");
        k_mem_slab_free(&uart_rx_slab, buf);
        return err;
    }

    //printk("UART baudrate changed to %d\n", baudrate);

    return 0;
}


static void AppUartTxThread(void* arg1, void* arg2, void* arg3)
{
    ARG_UNUSED(arg1);
    ARG_UNUSED(arg2);
    ARG_UNUSED(arg3);

    struct uart_packet pkt;

    while (1)
    {
        k_msgq_get(&tx_msgq, &pkt, K_FOREVER);

        int err = uart_tx(UartDevice, pkt.data, pkt.len, SYS_FOREVER_US);
        if (err)
        {
            LOG_ERR("uart_tx failed: %d", err);
            k_free(pkt.data);
            continue;
        }

        k_sem_take(&tx_done, K_FOREVER);

        k_free(pkt.data);
    }
}

static void AppUartRxThread(void* arg1, void* arg2, void* arg3)
{
    ARG_UNUSED(arg1);
    ARG_UNUSED(arg2);
    ARG_UNUSED(arg3);

    struct uart_packet pkt;

    while (1)
    {
        k_msgq_get(&rx_msgq, &pkt, K_FOREVER);

        if (user_rx_cb)
        {
            user_rx_cb(pkt.data, pkt.len);
        }
        else
        {
            k_free(pkt.data);
        }
    }
}

K_THREAD_DEFINE(tx_tid, 1024, AppUartTxThread, NULL, NULL, NULL, 5, 0, 0);
K_THREAD_DEFINE(rx_tid, 1024, AppUartRxThread, NULL, NULL, NULL, 5, 0, 0);

SYS_INIT(AppUartInit, APPLICATION, CONFIG_APPLICATION_INIT_PRIORITY);
```

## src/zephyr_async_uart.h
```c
#ifndef __ZEPHYR_ASYNC_UART_H
#define __ZEPHYR_ASYNC_UART_H

#include <stddef.h>
#include <stdint.h>

#define SERIAL_CMD_BUFF_SIZE    (256)
#define SERIAL_SEND_BUFFER_SIZE (256)
#define SERIAL_CMD_ADD_MAX      (3)
#define SERIAL_CMD_ADD_ERR      (4)

#ifdef __cplusplus
extern "C" {
#endif

    typedef void (*packets_cb_t)(uint8_t* data, size_t len);

    int UartRxCbRegister(packets_cb_t cb);
    int SerialSendMsg(const uint8_t* data, size_t len);

    extern uint8_t Serial_ucAckBuffer[SERIAL_CMD_BUFF_SIZE];


    uint8_t Hex2Char(uint8_t c, bool* pbOk);
    extern bool gImuOutputEnabled;
    extern bool gImuReinitFlag;
    extern bool gImuSerialOutputEnabled;


    void SendOnlyNAck(void);
    void SendAck(void);
    void SendERRWriteAck(uint8_t u8Addr, uint8_t rel);
    void SendReadWriteAck(uint8_t u8Addr, uint8_t u8Val);
    bool CheckSetCmdValidity(const uint8_t* pBuffer, uint32_t rxBytes,
        uint8_t* pAddrOfs, uint8_t* pRegVal);
    bool ProcessDSIMCCommand(uint8_t* pBuffer, uint32_t rxBytes);
    bool ProcessSerialBuffer(uint8_t* pBuffer, uint32_t* pRxBytes);
    int UartReconfig(uint32_t baudrate);




#ifdef __cplusplus
}
#endif

#endif
```

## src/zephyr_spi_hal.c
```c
#include "zephyr_spi_hal.h"

#define SPI_NODE DT_NODELABEL(spi2)
static const struct device* spi_dev = DEVICE_DT_GET(SPI_NODE);
static const struct device* gpio_b = DEVICE_DT_GET(DT_NODELABEL(gpiob));

#if defined(IMU_TARGET_IM3J)
#define CS_ACCEL_PIN 9 // PB9
#define CS_GYRO_PIN 8 // PB8
#define CS_EEPROM_PIN 4 // PB4

#elif defined(IMU_TARGET_IM8S)
#define CS_IMU_PIN 9 // PB9
#define CS_EEPROM_PIN 4 // PB4
#endif

static struct spi_config spi_cfg = {
	.frequency = 1000000,
	.operation = SPI_OP_MODE_MASTER |
				 SPI_TRANSFER_MSB |
				 SPI_WORD_SET(8),

	.slave = 0,
	.cs = NULL,
};

#define MAX_SPI_BUF_SIZE 256
__aligned(4) static uint8_t tx_buffer[MAX_SPI_BUF_SIZE];
__aligned(4) static uint8_t rx_buffer[MAX_SPI_BUF_SIZE];

void cs_select(DsImuChipId_t eChipId)
{

#if defined(IMU_TARGET_IM3J)
	switch (eChipId) {
		case DS_IM3J_ACC:
			gpio_pin_set(gpio_b, CS_ACCEL_PIN, 0);
			break;
		case DS_IM3J_GYR:
			gpio_pin_set(gpio_b, CS_GYRO_PIN, 0);
			break;
		case DS_EEPROM:
			gpio_pin_set(gpio_b, CS_EEPROM_PIN, 0);
			break;
		default:
			break;
	}

#elif defined(IMU_TARGET_IM8S)
	switch (eChipId) {
		case DS_IM8S_IMU:
			gpio_pin_set(gpio_b, CS_IMU_PIN, 0);
			break;
		case DS_EEPROM:
			gpio_pin_set(gpio_b, CS_EEPROM_PIN, 0);
			break;
		default:
			break;
	}
#endif

}

void cs_deselect(DsImuChipId_t eChipId)
{
#if defined(IMU_TARGET_IM3J)
	switch (eChipId) {
		case DS_IM3J_ACC:
			gpio_pin_set(gpio_b, CS_ACCEL_PIN, 1);
			break;
		case DS_IM3J_GYR:
			gpio_pin_set(gpio_b, CS_GYRO_PIN, 1);
			break;
		case DS_EEPROM:
			gpio_pin_set(gpio_b, CS_EEPROM_PIN, 1);
			break;
		default:
			break;
	}

#elif defined(IMU_TARGET_IM8S)
	switch (eChipId) {
		case DS_IM8S_IMU:
			gpio_pin_set(gpio_b, CS_IMU_PIN, 1);
			break;
		case DS_EEPROM:
			gpio_pin_set(gpio_b, CS_EEPROM_PIN, 1);
			break;
		default:
			break;
	}
#endif

}

uint8_t spiTransfer(DsImuChipId_t eChipId,
	DsImu_SpiBuffType* pxSpiBufArray,
	uint8_t u8ArraySize)
{
	if (!pxSpiBufArray || u8ArraySize == 0)
		return 1;
	for (int j = 0; j < pxSpiBufArray[0].u16Len && j < 16; j++)
		cs_select(eChipId);
	k_usleep(10);

	for (uint8_t i = 0; i < u8ArraySize; i++)
	{
		uint16_t len = pxSpiBufArray[i].u16Len;

		if (len == 0 || len > MAX_SPI_BUF_SIZE)
		{
			cs_deselect(eChipId);
			return 1;
		}

		memcpy(tx_buffer, pxSpiBufArray[i].pTxBuf, len);

		struct spi_buf tx_buf = {
			.buf = tx_buffer,
			.len = len };

		struct spi_buf rx_buf = {
			.buf = rx_buffer,
			.len = len };

		struct spi_buf_set tx_set = {
			.buffers = &tx_buf,
			.count = 1 };

		struct spi_buf_set rx_set = {
			.buffers = &rx_buf,
			.count = 1 };

		int ret = spi_transceive(spi_dev, &spi_cfg, &tx_set, &rx_set);
		if (ret != 0)
		{
			cs_deselect(eChipId);
			return 1;
		}
		memcpy(pxSpiBufArray[i].pRxBuf, rx_buffer, len);
	}

	cs_deselect(eChipId);

	return 0;
}

void spiCancel(DsImuChipId_t eChipId)
{
	cs_deselect(eChipId);
}

uint8_t spiGetTransferResult(DsImuChipId_t eChipId)
{
	return 0;
}

int Zephyr_SPI_GPIO_Init(void)
{
	if (!device_is_ready(gpio_b))
	{
		printk("GPIO not ready\n");
		return -1;
	}

#if defined(IMU_TARGET_IM3J)
	gpio_pin_configure(gpio_b, CS_ACCEL_PIN, GPIO_OUTPUT_HIGH);
	gpio_pin_configure(gpio_b, CS_GYRO_PIN, GPIO_OUTPUT_HIGH);
	gpio_pin_configure(gpio_b, CS_EEPROM_PIN, GPIO_OUTPUT_HIGH);

#elif defined(IMU_TARGET_IM8S)
	gpio_pin_configure(gpio_b, CS_IMU_PIN, GPIO_OUTPUT_HIGH);
	gpio_pin_configure(gpio_b, CS_EEPROM_PIN, GPIO_OUTPUT_HIGH);
#endif

	return 0;
}
```

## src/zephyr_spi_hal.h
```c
#ifndef ZEPHYR_SPI_HAL_H_
#define ZEPHYR_SPI_HAL_H_

#include <zephyr/kernel.h>
#include <zephyr/device.h>
#include <zephyr/drivers/spi.h>
#include <zephyr/drivers/gpio.h>
#include <zephyr/sys/printk.h>
#include <string.h>
#include "DsImuSdk.h"

void cs_select(DsImuChipId_t eChipId);
void cs_deselect(DsImuChipId_t eChipId);

uint8_t spiTransfer(DsImuChipId_t eChipId, DsImu_SpiBuffType* pxSpiBufArray, uint8_t u8ArraySize);
void spiCancel(DsImuChipId_t eChipId);
uint8_t spiGetTransferResult(DsImuChipId_t eChipId);

int Zephyr_SPI_GPIO_Init(void);

#endif
```

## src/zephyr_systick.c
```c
#include "zephyr_systick.h"
#include <zephyr/kernel.h>

static uint64_t cycles_per_sec = 0;

void TickInit(void)
{
    cycles_per_sec = sys_clock_hw_cycles_per_sec();
}

uint64_t GetTickUs(void)
{
    uint64_t cyc = k_cycle_get_64();

    return (cyc / cycles_per_sec) * 1000000ULL +
           (cyc % cycles_per_sec) * 1000000ULL / cycles_per_sec;
}
```

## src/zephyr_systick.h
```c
#ifndef ZEPHYR_SYSTICK_H_
#define ZEPHYR_SYSTICK_H_

#include <zephyr/kernel.h>

void TickInit(void);
uint64_t GetTickUs(void);

#endif
```
